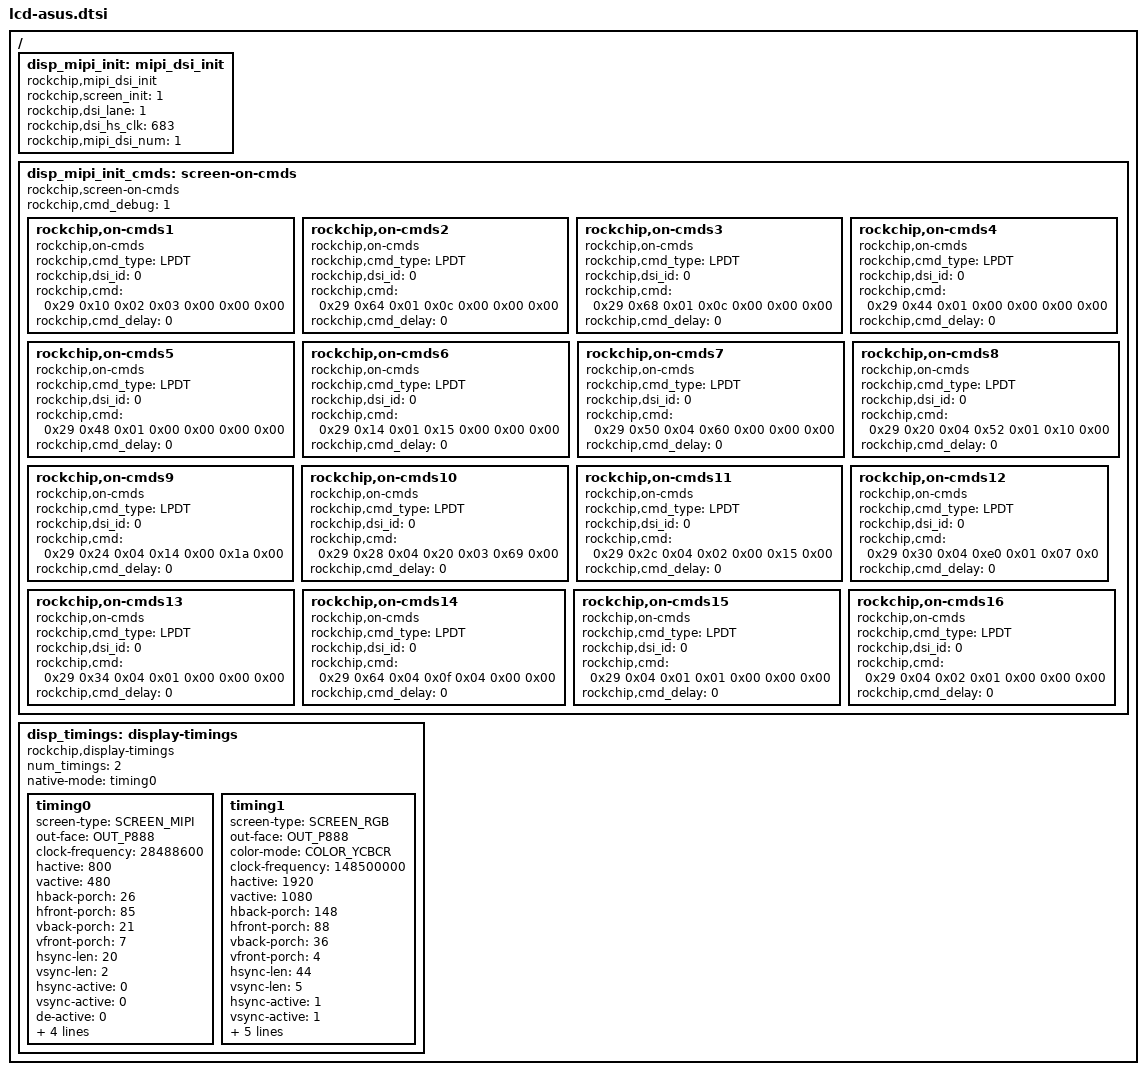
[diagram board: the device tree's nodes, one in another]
/*
 * Asus tinker board LCD BOX
 */

/ {
		/* about mipi */
		disp_mipi_init: mipi_dsi_init{
					compatible = "rockchip,mipi_dsi_init";
					rockchip,screen_init	= <1>;
					rockchip,dsi_lane		= <1>;
					rockchip,dsi_hs_clk		= <683>;
					rockchip,mipi_dsi_num	= <1>;
		};

		disp_mipi_init_cmds: screen-on-cmds {
					compatible = "rockchip,screen-on-cmds";
					rockchip,cmd_debug = <1>;
					rockchip,on-cmds1 {
							compatible = "rockchip,on-cmds";
							rockchip,cmd_type = <LPDT>;
							rockchip,dsi_id = <0>;
							rockchip,cmd = <0x29 0x10 0x02 0x03 0x00 0x00 0x00>;
							rockchip,cmd_delay = <0>;
					};
					rockchip,on-cmds2 {
							compatible = "rockchip,on-cmds";
							rockchip,cmd_type = <LPDT>;
							rockchip,dsi_id = <0>;
							rockchip,cmd = <0x29 0x64 0x01 0x0c 0x00 0x00 0x00>;
							rockchip,cmd_delay = <0>;
					};
					rockchip,on-cmds3 {
							compatible = "rockchip,on-cmds";
							rockchip,cmd_type = <LPDT>;
							rockchip,dsi_id = <0>;
							rockchip,cmd = <0x29 0x68 0x01 0x0c 0x00 0x00 0x00>;
							rockchip,cmd_delay = <0>;
					};
					rockchip,on-cmds4 {
							compatible = "rockchip,on-cmds";
							rockchip,cmd_type = <LPDT>;
							rockchip,dsi_id = <0>;
							rockchip,cmd = <0x29 0x44 0x01 0x00 0x00 0x00 0x00>;
							rockchip,cmd_delay = <0>;
					};
					rockchip,on-cmds5 {
							compatible = "rockchip,on-cmds";
							rockchip,cmd_type = <LPDT>;
							rockchip,dsi_id = <0>;
							rockchip,cmd = <0x29 0x48 0x01 0x00 0x00 0x00 0x00>;
							rockchip,cmd_delay = <0>;
					};
					rockchip,on-cmds6 {
							compatible = "rockchip,on-cmds";
							rockchip,cmd_type = <LPDT>;
							rockchip,dsi_id = <0>;
							rockchip,cmd = <0x29 0x14 0x01 0x15 0x00 0x00 0x00>;
							rockchip,cmd_delay = <0>;
					};
					rockchip,on-cmds7 {
							compatible = "rockchip,on-cmds";
							rockchip,cmd_type = <LPDT>;
							rockchip,dsi_id = <0>;
							rockchip,cmd = <0x29 0x50 0x04 0x60 0x00 0x00 0x00>;
							rockchip,cmd_delay = <0>;
					};
					rockchip,on-cmds8 {
							compatible = "rockchip,on-cmds";
							rockchip,cmd_type = <LPDT>;
							rockchip,dsi_id = <0>;
							rockchip,cmd = <0x29 0x20 0x04 0x52 0x01 0x10 0x00>;
							rockchip,cmd_delay = <0>;
					};
					rockchip,on-cmds9 {
							compatible = "rockchip,on-cmds";
							rockchip,cmd_type = <LPDT>;
							rockchip,dsi_id = <0>;
							rockchip,cmd = <0x29 0x24 0x04 0x14 0x00 0x1a 0x00>;
							rockchip,cmd_delay = <0>;
					};
					rockchip,on-cmds10 {
							compatible = "rockchip,on-cmds";
							rockchip,cmd_type = <LPDT>;
							rockchip,dsi_id = <0>;
							rockchip,cmd = <0x29 0x28 0x04 0x20 0x03 0x69 0x00>;
							rockchip,cmd_delay = <0>;
					};
					rockchip,on-cmds11 {
							compatible = "rockchip,on-cmds";
							rockchip,cmd_type = <LPDT>;
							rockchip,dsi_id = <0>;
							rockchip,cmd = <0x29 0x2c 0x04 0x02 0x00 0x15 0x00>;
							rockchip,cmd_delay = <0>;
					};
					rockchip,on-cmds12 {
							compatible = "rockchip,on-cmds";
							rockchip,cmd_type = <LPDT>;
							rockchip,dsi_id = <0>;
							rockchip,cmd = <0x29 0x30 0x04 0xe0 0x01 0x07 0x0>;
							rockchip,cmd_delay = <0>;
					};
					rockchip,on-cmds13 {
							compatible = "rockchip,on-cmds";
							rockchip,cmd_type = <LPDT>;
							rockchip,dsi_id = <0>;
							rockchip,cmd = <0x29 0x34 0x04 0x01 0x00 0x00 0x00>;
							rockchip,cmd_delay = <0>;
					};
					rockchip,on-cmds14 {
							compatible = "rockchip,on-cmds";
							rockchip,cmd_type = <LPDT>;
							rockchip,dsi_id = <0>;
							rockchip,cmd = <0x29 0x64 0x04 0x0f 0x04 0x00 0x00>;
							rockchip,cmd_delay = <0>;
					};
					rockchip,on-cmds15 {
							compatible = "rockchip,on-cmds";
							rockchip,cmd_type = <LPDT>;
							rockchip,dsi_id = <0>;
							rockchip,cmd = <0x29 0x04 0x01 0x01 0x00 0x00 0x00>;
							rockchip,cmd_delay = <0>;
					};
					rockchip,on-cmds16 {
							compatible = "rockchip,on-cmds";
							rockchip,cmd_type = <LPDT>;
							rockchip,dsi_id = <0>;
							rockchip,cmd = <0x29 0x04 0x02 0x01 0x00 0x00 0x00>;
							rockchip,cmd_delay = <0>;
					};
		};

		disp_timings: display-timings {
					num_timings = <2>;
					native-mode = <&timing0>;
					compatible = "rockchip,display-timings";
					timing0: timing0 {
						screen-type = <SCREEN_MIPI>;
						out-face  = <OUT_P888>;
						clock-frequency = <28488600>;
						hactive = <800>;
						vactive = <480>;
						hback-porch = <26>;
						hfront-porch = <85>;
						vback-porch = <21>;
						vfront-porch = <7>;
						hsync-len = <20>;
						vsync-len = <2>;
						hsync-active = <0>;
						vsync-active = <0>;
						de-active = <0>;
						pixelclk-active = <0>;
						swap-rb = <0>;
						swap-rg = <0>;
						swap-gb = <0>;
					};
					/*For HDMI 1080p setting*/
					timing1: timing1 {
						screen-type = <SCREEN_RGB>;
						out-face = <OUT_P888>;
						color-mode = <COLOR_YCBCR>;
						clock-frequency = <148500000>;
						hactive = <1920>;
						vactive = <1080>;
						hback-porch = <148>;
						hfront-porch = <88>;
						vback-porch = <36>;
						vfront-porch = <4>;
						hsync-len = <44>;
						vsync-len = <5>;
						hsync-active = <1>;
						vsync-active = <1>;
						de-active = <0>;
						pixelclk-active = <0>;
						swap-rb = <0>;
						swap-rg = <0>;
						swap-gb = <0>;
					};
		};
};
